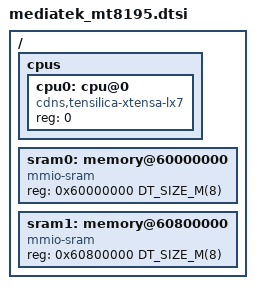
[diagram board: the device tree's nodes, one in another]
/*
 * Copyright (c) 2022 MediaTek
 *
 * SPDX-License-Identifier: Apache-2.0
 */

#include <xtensa/xtensa.dtsi>
#include <zephyr/dt-bindings/i2c/i2c.h>
#include <mem.h>

/ {
	cpus {
		#address-cells = <1>;
		#size-cells = <0>;

		cpu0: cpu@0 {
			device_type = "cpu";
			compatible = "cdns,tensilica-xtensa-lx7";
			reg = <0>;
		};
	};

	sram0: memory@60000000 {
		device_type = "memory";
		compatible = "mmio-sram";
		reg = <0x60000000 DT_SIZE_M(8)>;
	};

	sram1: memory@60800000 {
		device_type = "memory";
		compatible = "mmio-sram";
		reg = <0x60800000 DT_SIZE_M(8)>;
	};
};
